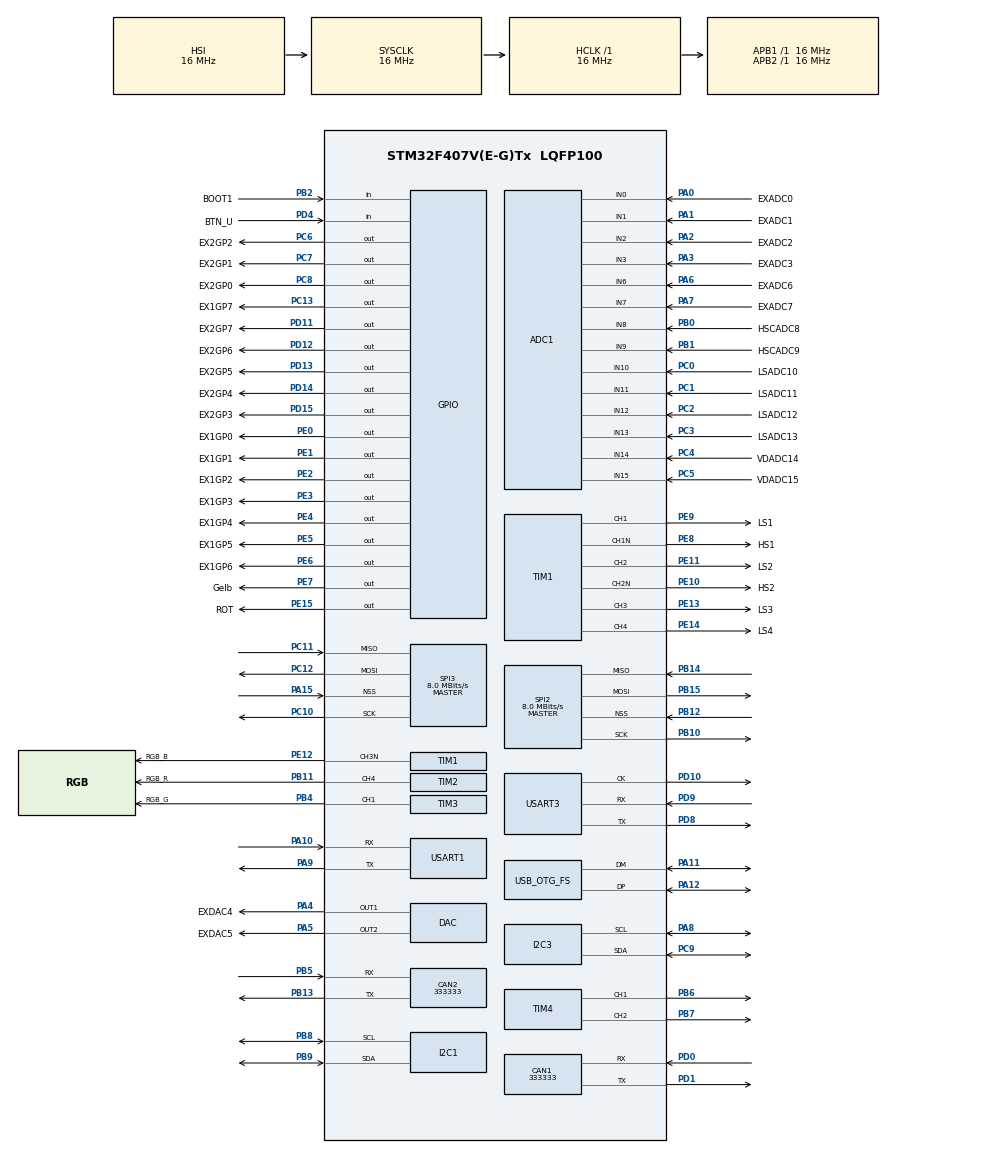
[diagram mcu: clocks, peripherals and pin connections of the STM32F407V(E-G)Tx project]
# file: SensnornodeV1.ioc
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ADC1.Channel-0\#ChannelRegularConversion=ADC_CHANNEL_10
ADC1.NbrOfConversionFlag=1
ADC1.Rank-0\#ChannelRegularConversion=1
ADC1.SamplingTime-0\#ChannelRegularConversion=ADC_SAMPLETIME_3CYCLES
ADC1.master=1
CAN1.CalculateBaudRate=333333
CAN1.CalculateTimeBit=3000
CAN1.CalculateTimeQuantum=1000.0
CAN2.CalculateBaudRate=333333
CAN2.CalculateTimeBit=3000
CAN2.CalculateTimeQuantum=1000.0
Mcu.Family=STM32F4
Mcu.Name=STM32F407V(E-G)Tx
Mcu.Package=LQFP100
NVIC.PriorityGroup=NVIC_PRIORITYGROUP_4
PA0-WKUP.GPIO_Label=EXADC0
PA0-WKUP.Signal=ADCx_IN0
PA1.GPIO_Label=EXADC1
PA1.Signal=ADCx_IN1
PA10.Mode=Asynchronous
PA10.Signal=USART1_RX
PA11.Mode=Device_Only
PA11.Signal=USB_OTG_FS_DM
PA12.Mode=Device_Only
PA12.Signal=USB_OTG_FS_DP
PA13.Mode=Trace_Asynchronous_SW
PA13.Signal=SYS_JTMS-SWDIO
PA14.Mode=Trace_Asynchronous_SW
PA14.Signal=SYS_JTCK-SWCLK
PA15.Mode=NSS_Signal_Hard_Input
PA15.Signal=SPI3_NSS
PA2.GPIO_Label=EXADC2
PA2.Signal=ADCx_IN2
PA3.GPIO_Label=EXADC3
PA3.Signal=ADCx_IN3
PA4.GPIO_Label=EXDAC4
PA4.Signal=COMP_DAC1_group
PA5.GPIO_Label=EXDAC5
PA5.Signal=COMP_DAC2_group
PA6.GPIO_Label=EXADC6
PA6.Signal=ADCx_IN6
PA7.GPIO_Label=EXADC7
PA7.Signal=ADCx_IN7
PA8.Mode=I2C
PA8.Signal=I2C3_SCL
PA9.Mode=Asynchronous
PA9.Signal=USART1_TX
PB0.GPIO_Label=HSCADC8
PB0.Signal=ADCx_IN8
PB1.GPIO_Label=HSCADC9
PB1.Signal=ADCx_IN9
PB10.Mode=Full_Duplex_Master
PB10.Signal=SPI2_SCK
PB11.GPIO_Label=RGB_R
PB11.Signal=S_TIM2_CH4
PB12.Mode=NSS_Signal_Hard_Input
PB12.Signal=SPI2_NSS
PB13.Mode=CAN_Activate
PB13.Signal=CAN2_TX
PB14.Mode=Full_Duplex_Master
PB14.Signal=SPI2_MISO
PB15.Mode=Full_Duplex_Master
PB15.Signal=SPI2_MOSI
PB2.GPIO_Label=BOOT1
PB2.Signal=GPIO_Input
PB3.Mode=Trace_Asynchronous_SW
PB3.Signal=SYS_JTDO-SWO
PB4.GPIO_Label=RGB_G
PB4.Signal=S_TIM3_CH1
PB5.Mode=CAN_Activate
PB5.Signal=CAN2_RX
PB6.Signal=S_TIM4_CH1
PB7.Signal=S_TIM4_CH2
PB8.Mode=I2C
PB8.Signal=I2C1_SCL
PB9.Mode=I2C
PB9.Signal=I2C1_SDA
PC0.GPIO_Label=LSADC10
PC0.Signal=ADCx_IN10
PC1.GPIO_Label=LSADC11
PC1.Signal=ADCx_IN11
PC10.Mode=Full_Duplex_Master
PC10.Signal=SPI3_SCK
PC11.Mode=Full_Duplex_Master
PC11.Signal=SPI3_MISO
PC12.Mode=Full_Duplex_Master
PC12.Signal=SPI3_MOSI
PC13-ANTI_TAMP.GPIO_Label=EX1GP7
PC13-ANTI_TAMP.Signal=GPIO_Output
PC2.GPIO_Label=LSADC12
PC2.Signal=ADCx_IN12
PC3.GPIO_Label=LSADC13
PC3.Signal=ADCx_IN13
PC4.GPIO_Label=VDADC14
PC4.Signal=ADCx_IN14
PC5.GPIO_Label=VDADC15
PC5.Signal=ADCx_IN15
PC6.GPIO_Label=EX2GP2
PC6.Signal=GPIO_Output
PC7.GPIO_Label=EX2GP1
PC7.Signal=GPIO_Output
PC8.GPIO_Label=EX2GP0
PC8.Signal=GPIO_Output
PC9.Mode=I2C
PC9.Signal=I2C3_SDA
PD0.Mode=CAN_Activate
PD0.Signal=CAN1_RX
PD1.Mode=CAN_Activate
PD1.Signal=CAN1_TX
PD10.Mode=Synchronous
PD10.Signal=USART3_CK
PD11.GPIO_Label=EX2GP7
PD11.Signal=GPIO_Output
PD12.GPIO_Label=EX2GP6
PD12.Signal=GPIO_Output
PD13.GPIO_Label=EX2GP5
PD13.Signal=GPIO_Output
PD14.GPIO_Label=EX2GP4
PD14.Signal=GPIO_Output
PD15.GPIO_Label=EX2GP3
PD15.Signal=GPIO_Output
PD4.GPIO_Label=BTN_U
PD4.Signal=GPIO_Input
PD8.Mode=Synchronous
PD8.Signal=USART3_TX
PD9.Mode=Synchronous
PD9.Signal=USART3_RX
PE0.GPIO_Label=EX1GP0
PE0.Signal=GPIO_Output
PE1.GPIO_Label=EX1GP1
PE1.Signal=GPIO_Output
PE10.GPIO_Label=HS2
PE10.Mode=PWM Generation2 CH2 CH2N
PE10.Signal=TIM1_CH2N
PE11.GPIO_Label=LS2
PE11.Signal=S_TIM1_CH2
PE12.GPIO_Label=RGB_B
PE12.Mode=PWM Generation3 CH3 CH3N
PE12.Signal=TIM1_CH3N
PE13.GPIO_Label=LS3
PE13.Signal=S_TIM1_CH3
PE14.GPIO_Label=LS4
PE14.Signal=S_TIM1_CH4
PE15.GPIO_Label=ROT
PE15.Signal=GPIO_Output
PE2.GPIO_Label=EX1GP2
PE2.Signal=GPIO_Output
PE3.GPIO_Label=EX1GP3
PE3.Signal=GPIO_Output
PE4.GPIO_Label=EX1GP4
PE4.Signal=GPIO_Output
PE5.GPIO_Label=EX1GP5
PE5.Signal=GPIO_Output
PE6.GPIO_Label=EX1GP6
PE6.Signal=GPIO_Output
PE7.GPIO_Label=Gelb
PE7.Signal=GPIO_Output
PE8.GPIO_Label=HS1
PE8.Mode=PWM Generation1 CH1 CH1N
PE8.Signal=TIM1_CH1N
PE9.GPIO_Label=LS1
PE9.Signal=S_TIM1_CH1
PH0-OSC_IN.Mode=HSE-External-Oscillator
PH0-OSC_IN.Signal=RCC_OSC_IN
PH1-OSC_OUT.Mode=HSE-External-Oscillator
PH1-OSC_OUT.Signal=RCC_OSC_OUT
ProjectManager.HeapSize=0x200
ProjectManager.StackSize=0x400
ProjectManager.TargetToolchain=CMake
RCC.48MHZClocksFreq_Value=48000000
RCC.AHBFreq_Value=16000000
RCC.APB1Freq_Value=16000000
RCC.APB2Freq_Value=16000000
RCC.CortexFreq_Value=16000000
RCC.HSE_VALUE=25000000
RCC.HSI_VALUE=16000000
RCC.LSE_VALUE=32768
RCC.PLLM=15
RCC.PLLN=144
RCC.PLLQ=5
RCC.SYSCLKFreq_VALUE=16000000
RCC.VCOOutputFreq_Value=240000000
SH.ADCx_IN0.0=ADC1_IN0,IN0
SH.ADCx_IN1.0=ADC1_IN1,IN1
SH.ADCx_IN10.0=ADC1_IN10,IN10
SH.ADCx_IN11.0=ADC1_IN11,IN11
SH.ADCx_IN12.0=ADC1_IN12,IN12
SH.ADCx_IN13.0=ADC1_IN13,IN13
SH.ADCx_IN14.0=ADC1_IN14,IN14
SH.ADCx_IN15.0=ADC1_IN15,IN15
SH.ADCx_IN2.0=ADC1_IN2,IN2
SH.ADCx_IN3.0=ADC1_IN3,IN3
SH.ADCx_IN6.0=ADC1_IN6,IN6
SH.ADCx_IN7.0=ADC1_IN7,IN7
SH.ADCx_IN8.0=ADC1_IN8,IN8
SH.ADCx_IN9.0=ADC1_IN9,IN9
SH.COMP_DAC1_group.0=DAC_OUT1,DAC_OUT1
SH.COMP_DAC2_group.0=DAC_OUT2,DAC_OUT2
SH.S_TIM1_CH1.0=TIM1_CH1,PWM Generation1 CH1 CH1N
SH.S_TIM1_CH2.0=TIM1_CH2,PWM Generation2 CH2 CH2N
SH.S_TIM1_CH3.0=TIM1_CH3,PWM Generation3 CH3 CH3N
SH.S_TIM1_CH4.0=TIM1_CH4,PWM Generation4 CH4
SH.S_TIM2_CH4.0=TIM2_CH4,Forced Output4 CH4
SH.S_TIM3_CH1.0=TIM3_CH1,PWM Generation1 CH1
SH.S_TIM4_CH1.0=TIM4_CH1,PWM Generation1 CH1
SH.S_TIM4_CH2.0=TIM4_CH2,PWM Generation2 CH2
SPI2.CalculateBaudRate=8.0 MBits/s
SPI2.Direction=SPI_DIRECTION_2LINES
SPI2.Mode=SPI_MODE_MASTER
SPI2.VirtualNSS=VM_NSSHARD
SPI2.VirtualType=VM_MASTER
SPI3.CalculateBaudRate=8.0 MBits/s
SPI3.Direction=SPI_DIRECTION_2LINES
SPI3.Mode=SPI_MODE_MASTER
SPI3.VirtualNSS=VM_NSSHARD
SPI3.VirtualType=VM_MASTER
TIM1.Channel-PWM\ Generation1\ CH1\ CH1N=TIM_CHANNEL_1
TIM1.Channel-PWM\ Generation2\ CH2\ CH2N=TIM_CHANNEL_2
TIM1.Channel-PWM\ Generation3\ CH3\ CH3N=TIM_CHANNEL_3
TIM1.Channel-PWM\ Generation4\ CH4=TIM_CHANNEL_4
TIM2.Channel-Forced\ Output4\ CH4=TIM_CHANNEL_4
TIM3.Channel-PWM\ Generation1\ CH1=TIM_CHANNEL_1
TIM4.Channel-PWM\ Generation1\ CH1=TIM_CHANNEL_1
TIM4.Channel-PWM\ Generation2\ CH2=TIM_CHANNEL_2
USART1.VirtualMode=VM_ASYNC
USART3.VirtualMode=VM_SYNC
USB_OTG_FS.VirtualMode=Device_Only
board=custom

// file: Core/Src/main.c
/* USER CODE BEGIN Header */
/**
  ******************************************************************************
  * @file           : main.c
  * @brief          : Main program body
  ******************************************************************************
  * @attention
  *
  * Copyright (c) 2026 STMicroelectronics.
  * All rights reserved.
  *
  * This software is licensed under terms that can be found in the LICENSE file
  * in the root directory of this software component.
  * If no LICENSE file comes with this software, it is provided AS-IS.
  *
  ******************************************************************************
  */
/* USER CODE END Header */
#include "main.h"

/* USER CODE BEGIN Includes */
#include "Tester/TestMain.h"
/* USER CODE END Includes */

ADC_HandleTypeDef hadc1;

CAN_HandleTypeDef hcan1;
CAN_HandleTypeDef hcan2;

DAC_HandleTypeDef hdac;

I2C_HandleTypeDef hi2c1;
I2C_HandleTypeDef hi2c3;

SPI_HandleTypeDef hspi2;
SPI_HandleTypeDef hspi3;

TIM_HandleTypeDef htim1;
TIM_HandleTypeDef htim2;
TIM_HandleTypeDef htim3;
TIM_HandleTypeDef htim4;

UART_HandleTypeDef huart1;
USART_HandleTypeDef husart3;

PCD_HandleTypeDef hpcd_USB_OTG_FS;

void SystemClock_Config(void);
static void MX_GPIO_Init(void);
static void MX_ADC1_Init(void);
static void MX_CAN1_Init(void);
static void MX_CAN2_Init(void);
static void MX_DAC_Init(void);
static void MX_I2C1_Init(void);
static void MX_I2C3_Init(void);
static void MX_SPI2_Init(void);
static void MX_SPI3_Init(void);
static void MX_TIM1_Init(void);
static void MX_TIM2_Init(void);
static void MX_TIM3_Init(void);
static void MX_TIM4_Init(void);
static void MX_USART1_UART_Init(void);
static void MX_USART3_Init(void);
static void MX_USB_OTG_FS_PCD_Init(void);

int main(void)
{

  /* MCU Configuration--------------------------------------------------------*/

  /* Reset of all peripherals, Initializes the Flash interface and the Systick. */
  HAL_Init();

  /* Configure the system clock */
  SystemClock_Config();

  /* Initialize all configured peripherals */
  MX_GPIO_Init();
  MX_ADC1_Init();
  MX_CAN1_Init();
  MX_CAN2_Init();
  MX_DAC_Init();
  MX_I2C1_Init();
  MX_I2C3_Init();
  MX_SPI2_Init();
  MX_SPI3_Init();
  MX_TIM1_Init();
  MX_TIM2_Init();
  MX_TIM3_Init();
  MX_TIM4_Init();
  MX_USART1_UART_Init();
  MX_USART3_Init();
  MX_USB_OTG_FS_PCD_Init();

  /* Infinite loop */
  while (1)
  {

  while (1)
  {
  }
}

void SystemClock_Config(void)
{
  RCC_OscInitTypeDef RCC_OscInitStruct = {0};
  RCC_ClkInitTypeDef RCC_ClkInitStruct = {0};

  /** Configure the main internal regulator output voltage
  */
  __HAL_RCC_PWR_CLK_ENABLE();
  __HAL_PWR_VOLTAGESCALING_CONFIG(PWR_REGULATOR_VOLTAGE_SCALE1);

  /** Initializes the RCC Oscillators according to the specified parameters
  * in the RCC_OscInitTypeDef structure.
  */
  RCC_OscInitStruct.OscillatorType = RCC_OSCILLATORTYPE_HSI|RCC_OSCILLATORTYPE_HSE;
  RCC_OscInitStruct.HSEState = RCC_HSE_ON;
  RCC_OscInitStruct.HSIState = RCC_HSI_ON;
  RCC_OscInitStruct.HSICalibrationValue = RCC_HSICALIBRATION_DEFAULT;
  RCC_OscInitStruct.PLL.PLLState = RCC_PLL_ON;
  RCC_OscInitStruct.PLL.PLLSource = RCC_PLLSOURCE_HSE;
  RCC_OscInitStruct.PLL.PLLM = 15;
  RCC_OscInitStruct.PLL.PLLN = 144;
  RCC_OscInitStruct.PLL.PLLP = RCC_PLLP_DIV2;
  RCC_OscInitStruct.PLL.PLLQ = 5;
  if (HAL_RCC_OscConfig(&RCC_OscInitStruct) != HAL_OK)
  {
    Error_Handler();
  }

  /** Initializes the CPU, AHB and APB buses clocks
  */
  RCC_ClkInitStruct.ClockType = RCC_CLOCKTYPE_HCLK|RCC_CLOCKTYPE_SYSCLK
                              |RCC_CLOCKTYPE_PCLK1|RCC_CLOCKTYPE_PCLK2;
  RCC_ClkInitStruct.SYSCLKSource = RCC_SYSCLKSOURCE_HSI;
  RCC_ClkInitStruct.AHBCLKDivider = RCC_SYSCLK_DIV1;
  RCC_ClkInitStruct.APB1CLKDivider = RCC_HCLK_DIV1;
  RCC_ClkInitStruct.APB2CLKDivider = RCC_HCLK_DIV1;

  if (HAL_RCC_ClockConfig(&RCC_ClkInitStruct, FLASH_LATENCY_0) != HAL_OK)
  {
    Error_Handler();
  }
}

static void MX_ADC1_Init(void)
{

  ADC_ChannelConfTypeDef sConfig = {0};

  /** Configure the global features of the ADC (Clock, Resolution, Data Alignment and number of conversion)
  */
  hadc1.Instance = ADC1;
  hadc1.Init.ClockPrescaler = ADC_CLOCK_SYNC_PCLK_DIV2;
  hadc1.Init.Resolution = ADC_RESOLUTION_12B;
  hadc1.Init.ScanConvMode = DISABLE;
  hadc1.Init.ContinuousConvMode = DISABLE;
  hadc1.Init.DiscontinuousConvMode = DISABLE;
  hadc1.Init.ExternalTrigConvEdge = ADC_EXTERNALTRIGCONVEDGE_NONE;
  hadc1.Init.ExternalTrigConv = ADC_SOFTWARE_START;
  hadc1.Init.DataAlign = ADC_DATAALIGN_RIGHT;
  hadc1.Init.NbrOfConversion = 1;
  hadc1.Init.DMAContinuousRequests = DISABLE;
  hadc1.Init.EOCSelection = ADC_EOC_SINGLE_CONV;
  if (HAL_ADC_Init(&hadc1) != HAL_OK)
  {
    Error_Handler();
  }

  /** Configure for the selected ADC regular channel its corresponding rank in the sequencer and its sample time.
  */
  sConfig.Channel = ADC_CHANNEL_10;
  sConfig.Rank = 1;
  sConfig.SamplingTime = ADC_SAMPLETIME_3CYCLES;
  if (HAL_ADC_ConfigChannel(&hadc1, &sConfig) != HAL_OK)
  {
    Error_Handler();
  }

}

static void MX_CAN1_Init(void)
{

  hcan1.Instance = CAN1;
  hcan1.Init.Prescaler = 16;
  hcan1.Init.Mode = CAN_MODE_NORMAL;
  hcan1.Init.SyncJumpWidth = CAN_SJW_1TQ;
  hcan1.Init.TimeSeg1 = CAN_BS1_1TQ;
  hcan1.Init.TimeSeg2 = CAN_BS2_1TQ;
  hcan1.Init.TimeTriggeredMode = DISABLE;
  hcan1.Init.AutoBusOff = DISABLE;
  hcan1.Init.AutoWakeUp = DISABLE;
  hcan1.Init.AutoRetransmission = DISABLE;
  hcan1.Init.ReceiveFifoLocked = DISABLE;
  hcan1.Init.TransmitFifoPriority = DISABLE;
  if (HAL_CAN_Init(&hcan1) != HAL_OK)
  {
    Error_Handler();
  }

}

static void MX_CAN2_Init(void)
{

  hcan2.Instance = CAN2;
  hcan2.Init.Prescaler = 16;
  hcan2.Init.Mode = CAN_MODE_NORMAL;
  hcan2.Init.SyncJumpWidth = CAN_SJW_1TQ;
  hcan2.Init.TimeSeg1 = CAN_BS1_1TQ;
  hcan2.Init.TimeSeg2 = CAN_BS2_1TQ;
  hcan2.Init.TimeTriggeredMode = DISABLE;
  hcan2.Init.AutoBusOff = DISABLE;
  hcan2.Init.AutoWakeUp = DISABLE;
  hcan2.Init.AutoRetransmission = DISABLE;
  hcan2.Init.ReceiveFifoLocked = DISABLE;
  hcan2.Init.TransmitFifoPriority = DISABLE;
  if (HAL_CAN_Init(&hcan2) != HAL_OK)
  {
    Error_Handler();
  }

}

static void MX_DAC_Init(void)
{

  DAC_ChannelConfTypeDef sConfig = {0};

  /** DAC Initialization
  */
  hdac.Instance = DAC;
  if (HAL_DAC_Init(&hdac) != HAL_OK)
  {
    Error_Handler();
  }

  /** DAC channel OUT1 config
  */
  sConfig.DAC_Trigger = DAC_TRIGGER_NONE;
  sConfig.DAC_OutputBuffer = DAC_OUTPUTBUFFER_ENABLE;
  if (HAL_DAC_ConfigChannel(&hdac, &sConfig, DAC_CHANNEL_1) != HAL_OK)
  {
    Error_Handler();
  }

  /** DAC channel OUT2 config
  */
  if (HAL_DAC_ConfigChannel(&hdac, &sConfig, DAC_CHANNEL_2) != HAL_OK)
  {
    Error_Handler();
  }

}

static void MX_I2C1_Init(void)
{

  hi2c1.Instance = I2C1;
  hi2c1.Init.ClockSpeed = 100000;
  hi2c1.Init.DutyCycle = I2C_DUTYCYCLE_2;
  hi2c1.Init.OwnAddress1 = 0;
  hi2c1.Init.AddressingMode = I2C_ADDRESSINGMODE_7BIT;
  hi2c1.Init.DualAddressMode = I2C_DUALADDRESS_DISABLE;
  hi2c1.Init.OwnAddress2 = 0;
  hi2c1.Init.GeneralCallMode = I2C_GENERALCALL_DISABLE;
  hi2c1.Init.NoStretchMode = I2C_NOSTRETCH_DISABLE;
  if (HAL_I2C_Init(&hi2c1) != HAL_OK)
  {
    Error_Handler();
  }

}

static void MX_I2C3_Init(void)
{

  hi2c3.Instance = I2C3;
  hi2c3.Init.ClockSpeed = 100000;
  hi2c3.Init.DutyCycle = I2C_DUTYCYCLE_2;
  hi2c3.Init.OwnAddress1 = 0;
  hi2c3.Init.AddressingMode = I2C_ADDRESSINGMODE_7BIT;
  hi2c3.Init.DualAddressMode = I2C_DUALADDRESS_DISABLE;
  hi2c3.Init.OwnAddress2 = 0;
  hi2c3.Init.GeneralCallMode = I2C_GENERALCALL_DISABLE;
  hi2c3.Init.NoStretchMode = I2C_NOSTRETCH_DISABLE;
  if (HAL_I2C_Init(&hi2c3) != HAL_OK)
  {
    Error_Handler();
  }

}

static void MX_SPI2_Init(void)
{

  /* SPI2 parameter configuration*/
  hspi2.Instance = SPI2;
  hspi2.Init.Mode = SPI_MODE_MASTER;
  hspi2.Init.Direction = SPI_DIRECTION_2LINES;
  hspi2.Init.DataSize = SPI_DATASIZE_8BIT;
  hspi2.Init.CLKPolarity = SPI_POLARITY_LOW;
  hspi2.Init.CLKPhase = SPI_PHASE_1EDGE;
  hspi2.Init.NSS = SPI_NSS_HARD_INPUT;
  hspi2.Init.BaudRatePrescaler = SPI_BAUDRATEPRESCALER_2;
  hspi2.Init.FirstBit = SPI_FIRSTBIT_MSB;
  hspi2.Init.TIMode = SPI_TIMODE_DISABLE;
  hspi2.Init.CRCCalculation = SPI_CRCCALCULATION_DISABLE;
  hspi2.Init.CRCPolynomial = 10;
  if (HAL_SPI_Init(&hspi2) != HAL_OK)
  {
    Error_Handler();
  }

}

static void MX_SPI3_Init(void)
{

  /* SPI3 parameter configuration*/
  hspi3.Instance = SPI3;
  hspi3.Init.Mode = SPI_MODE_MASTER;
  hspi3.Init.Direction = SPI_DIRECTION_2LINES;
  hspi3.Init.DataSize = SPI_DATASIZE_8BIT;
  hspi3.Init.CLKPolarity = SPI_POLARITY_LOW;
  hspi3.Init.CLKPhase = SPI_PHASE_1EDGE;
  hspi3.Init.NSS = SPI_NSS_HARD_INPUT;
  hspi3.Init.BaudRatePrescaler = SPI_BAUDRATEPRESCALER_2;
  hspi3.Init.FirstBit = SPI_FIRSTBIT_MSB;
  hspi3.Init.TIMode = SPI_TIMODE_DISABLE;
  hspi3.Init.CRCCalculation = SPI_CRCCALCULATION_DISABLE;
  hspi3.Init.CRCPolynomial = 10;
  if (HAL_SPI_Init(&hspi3) != HAL_OK)
  {
    Error_Handler();
  }

}

static void MX_TIM1_Init(void)
{

  TIM_MasterConfigTypeDef sMasterConfig = {0};
  TIM_OC_InitTypeDef sConfigOC = {0};
  TIM_BreakDeadTimeConfigTypeDef sBreakDeadTimeConfig = {0};

  htim1.Instance = TIM1;
  htim1.Init.Prescaler = 0;
  htim1.Init.CounterMode = TIM_COUNTERMODE_UP;
  htim1.Init.Period = 65535;
  htim1.Init.ClockDivision = TIM_CLOCKDIVISION_DIV1;
  htim1.Init.RepetitionCounter = 0;
  htim1.Init.AutoReloadPreload = TIM_AUTORELOAD_PRELOAD_DISABLE;
  if (HAL_TIM_PWM_Init(&htim1) != HAL_OK)
  {
    Error_Handler();
  }
  sMasterConfig.MasterOutputTrigger = TIM_TRGO_RESET;
  sMasterConfig.MasterSlaveMode = TIM_MASTERSLAVEMODE_DISABLE;
  if (HAL_TIMEx_MasterConfigSynchronization(&htim1, &sMasterConfig) != HAL_OK)
  {
    Error_Handler();
  }
  sConfigOC.OCMode = TIM_OCMODE_PWM1;
  sConfigOC.Pulse = 0;
  sConfigOC.OCPolarity = TIM_OCPOLARITY_HIGH;
  sConfigOC.OCNPolarity = TIM_OCNPOLARITY_HIGH;
  sConfigOC.OCFastMode = TIM_OCFAST_DISABLE;
  sConfigOC.OCIdleState = TIM_OCIDLESTATE_RESET;
  sConfigOC.OCNIdleState = TIM_OCNIDLESTATE_RESET;
  if (HAL_TIM_PWM_ConfigChannel(&htim1, &sConfigOC, TIM_CHANNEL_1) != HAL_OK)
  {
    Error_Handler();
  }
  if (HAL_TIM_PWM_ConfigChannel(&htim1, &sConfigOC, TIM_CHANNEL_2) != HAL_OK)
  {
    Error_Handler();
  }
  if (HAL_TIM_PWM_ConfigChannel(&htim1, &sConfigOC, TIM_CHANNEL_3) != HAL_OK)
  {
    Error_Handler();
  }
  if (HAL_TIM_PWM_ConfigChannel(&htim1, &sConfigOC, TIM_CHANNEL_4) != HAL_OK)
  {
    Error_Handler();
  }
  sBreakDeadTimeConfig.OffStateRunMode = TIM_OSSR_DISABLE;
  sBreakDeadTimeConfig.OffStateIDLEMode = TIM_OSSI_DISABLE;
  sBreakDeadTimeConfig.LockLevel = TIM_LOCKLEVEL_OFF;
  sBreakDeadTimeConfig.DeadTime = 0;
  sBreakDeadTimeConfig.BreakState = TIM_BREAK_DISABLE;
  sBreakDeadTimeConfig.BreakPolarity = TIM_BREAKPOLARITY_HIGH;
  sBreakDeadTimeConfig.AutomaticOutput = TIM_AUTOMATICOUTPUT_DISABLE;
  if (HAL_TIMEx_ConfigBreakDeadTime(&htim1, &sBreakDeadTimeConfig) != HAL_OK)
  {
    Error_Handler();
  }
  HAL_TIM_MspPostInit(&htim1);

}

static void MX_TIM2_Init(void)
{

  TIM_MasterConfigTypeDef sMasterConfig = {0};
  TIM_OC_InitTypeDef sConfigOC = {0};

  htim2.Instance = TIM2;
  htim2.Init.Prescaler = 0;
  htim2.Init.CounterMode = TIM_COUNTERMODE_UP;
  htim2.Init.Period = 4294967295;
  htim2.Init.ClockDivision = TIM_CLOCKDIVISION_DIV1;
  htim2.Init.AutoReloadPreload = TIM_AUTORELOAD_PRELOAD_DISABLE;
  if (HAL_TIM_OC_Init(&htim2) != HAL_OK)
  {
    Error_Handler();
  }
  sMasterConfig.MasterOutputTrigger = TIM_TRGO_RESET;
  sMasterConfig.MasterSlaveMode = TIM_MASTERSLAVEMODE_DISABLE;
  if (HAL_TIMEx_MasterConfigSynchronization(&htim2, &sMasterConfig) != HAL_OK)
  {
    Error_Handler();
  }
  sConfigOC.OCMode = TIM_OCMODE_FORCED_ACTIVE;
  sConfigOC.Pulse = 0;
  sConfigOC.OCPolarity = TIM_OCPOLARITY_HIGH;
  sConfigOC.OCFastMode = TIM_OCFAST_DISABLE;
  if (HAL_TIM_OC_ConfigChannel(&htim2, &sConfigOC, TIM_CHANNEL_4) != HAL_OK)
  {
    Error_Handler();
  }
  HAL_TIM_MspPostInit(&htim2);

}

static void MX_TIM3_Init(void)
{

  TIM_MasterConfigTypeDef sMasterConfig = {0};
  TIM_OC_InitTypeDef sConfigOC = {0};

  htim3.Instance = TIM3;
  htim3.Init.Prescaler = 0;
  htim3.Init.CounterMode = TIM_COUNTERMODE_UP;
  htim3.Init.Period = 65535;
  htim3.Init.ClockDivision = TIM_CLOCKDIVISION_DIV1;
  htim3.Init.AutoReloadPreload = TIM_AUTORELOAD_PRELOAD_DISABLE;
  if (HAL_TIM_PWM_Init(&htim3) != HAL_OK)
  {
    Error_Handler();
  }
  sMasterConfig.MasterOutputTrigger = TIM_TRGO_RESET;
  sMasterConfig.MasterSlaveMode = TIM_MASTERSLAVEMODE_DISABLE;
  if (HAL_TIMEx_MasterConfigSynchronization(&htim3, &sMasterConfig) != HAL_OK)
  {
    Error_Handler();
  }
  sConfigOC.OCMode = TIM_OCMODE_PWM1;
  sConfigOC.Pulse = 0;
  sConfigOC.OCPolarity = TIM_OCPOLARITY_HIGH;
  sConfigOC.OCFastMode = TIM_OCFAST_DISABLE;
  if (HAL_TIM_PWM_ConfigChannel(&htim3, &sConfigOC, TIM_CHANNEL_1) != HAL_OK)
  {
    Error_Handler();
  }
  HAL_TIM_MspPostInit(&htim3);

}

static void MX_TIM4_Init(void)
{

  TIM_MasterConfigTypeDef sMasterConfig = {0};
  TIM_OC_InitTypeDef sConfigOC = {0};

  htim4.Instance = TIM4;
  htim4.Init.Prescaler = 0;
  htim4.Init.CounterMode = TIM_COUNTERMODE_UP;
  htim4.Init.Period = 65535;
  htim4.Init.ClockDivision = TIM_CLOCKDIVISION_DIV1;
  htim4.Init.AutoReloadPreload = TIM_AUTORELOAD_PRELOAD_DISABLE;
  if (HAL_TIM_PWM_Init(&htim4) != HAL_OK)
  {
    Error_Handler();
  }
  sMasterConfig.MasterOutputTrigger = TIM_TRGO_RESET;
  sMasterConfig.MasterSlaveMode = TIM_MASTERSLAVEMODE_DISABLE;
  if (HAL_TIMEx_MasterConfigSynchronization(&htim4, &sMasterConfig) != HAL_OK)
  {
    Error_Handler();
  }
  sConfigOC.OCMode = TIM_OCMODE_PWM1;
  sConfigOC.Pulse = 0;
  sConfigOC.OCPolarity = TIM_OCPOLARITY_HIGH;
  sConfigOC.OCFastMode = TIM_OCFAST_DISABLE;
  if (HAL_TIM_PWM_ConfigChannel(&htim4, &sConfigOC, TIM_CHANNEL_1) != HAL_OK)
  {
    Error_Handler();
  }
  if (HAL_TIM_PWM_ConfigChannel(&htim4, &sConfigOC, TIM_CHANNEL_2) != HAL_OK)
  {
    Error_Handler();
  }
  HAL_TIM_MspPostInit(&htim4);

}

static void MX_USART1_UART_Init(void)
{

  huart1.Instance = USART1;
  huart1.Init.BaudRate = 115200;
  huart1.Init.WordLength = UART_WORDLENGTH_8B;
  huart1.Init.StopBits = UART_STOPBITS_1;
  huart1.Init.Parity = UART_PARITY_NONE;
  huart1.Init.Mode = UART_MODE_TX_RX;
  huart1.Init.HwFlowCtl = UART_HWCONTROL_NONE;
  huart1.Init.OverSampling = UART_OVERSAMPLING_16;
  if (HAL_UART_Init(&huart1) != HAL_OK)
  {
    Error_Handler();
  }

}

static void MX_USART3_Init(void)
{

  husart3.Instance = USART3;
  husart3.Init.BaudRate = 115200;
  husart3.Init.WordLength = USART_WORDLENGTH_8B;
  husart3.Init.StopBits = USART_STOPBITS_1;
  husart3.Init.Parity = USART_PARITY_NONE;
  husart3.Init.Mode = USART_MODE_TX_RX;
  husart3.Init.CLKPolarity = USART_POLARITY_LOW;
  husart3.Init.CLKPhase = USART_PHASE_1EDGE;
  husart3.Init.CLKLastBit = USART_LASTBIT_DISABLE;
  if (HAL_USART_Init(&husart3) != HAL_OK)
  {
    Error_Handler();
  }

}

static void MX_USB_OTG_FS_PCD_Init(void)
{

  hpcd_USB_OTG_FS.Instance = USB_OTG_FS;
  hpcd_USB_OTG_FS.Init.dev_endpoints = 4;
  hpcd_USB_OTG_FS.Init.speed = PCD_SPEED_FULL;
  hpcd_USB_OTG_FS.Init.dma_enable = DISABLE;
  hpcd_USB_OTG_FS.Init.phy_itface = PCD_PHY_EMBEDDED;
  hpcd_USB_OTG_FS.Init.Sof_enable = DISABLE;
  hpcd_USB_OTG_FS.Init.low_power_enable = DISABLE;
  hpcd_USB_OTG_FS.Init.lpm_enable = DISABLE;
  hpcd_USB_OTG_FS.Init.vbus_sensing_enable = DISABLE;
  hpcd_USB_OTG_FS.Init.use_dedicated_ep1 = DISABLE;
  if (HAL_PCD_Init(&hpcd_USB_OTG_FS) != HAL_OK)
  {
    Error_Handler();
  }

}

static void MX_GPIO_Init(void)
{
  GPIO_InitTypeDef GPIO_InitStruct = {0};

  /* GPIO Ports Clock Enable */
  __HAL_RCC_GPIOE_CLK_ENABLE();
  __HAL_RCC_GPIOC_CLK_ENABLE();
  __HAL_RCC_GPIOH_CLK_ENABLE();
  __HAL_RCC_GPIOA_CLK_ENABLE();
  __HAL_RCC_GPIOB_CLK_ENABLE();
  __HAL_RCC_GPIOD_CLK_ENABLE();

  /*Configure GPIO pin Output Level */
  HAL_GPIO_WritePin(GPIOE, EX1GP2_Pin|EX1GP3_Pin|EX1GP4_Pin|EX1GP5_Pin
                          |EX1GP6_Pin|Gelb_Pin|ROT_Pin|EX1GP0_Pin
                          |EX1GP1_Pin, GPIO_PIN_RESET);

  /*Configure GPIO pin Output Level */
  HAL_GPIO_WritePin(GPIOC, EX1GP7_Pin|EX2GP2_Pin|EX2GP1_Pin|EX2GP0_Pin, GPIO_PIN_RESET);

  /*Configure GPIO pin Output Level */
  HAL_GPIO_WritePin(GPIOD, EX2GP7_Pin|EX2GP6_Pin|EX2GP5_Pin|EX2GP4_Pin
                          |EX2GP3_Pin, GPIO_PIN_RESET);

  /*Configure GPIO pins : EX1GP2_Pin EX1GP3_Pin EX1GP4_Pin EX1GP5_Pin
                           EX1GP6_Pin Gelb_Pin ROT_Pin EX1GP0_Pin
                           EX1GP1_Pin */
  GPIO_InitStruct.Pin = EX1GP2_Pin|EX1GP3_Pin|EX1GP4_Pin|EX1GP5_Pin
                          |EX1GP6_Pin|Gelb_Pin|ROT_Pin|EX1GP0_Pin
                          |EX1GP1_Pin;
  GPIO_InitStruct.Mode = GPIO_MODE_OUTPUT_PP;
  GPIO_InitStruct.Pull = GPIO_NOPULL;
  GPIO_InitStruct.Speed = GPIO_SPEED_FREQ_LOW;
  HAL_GPIO_Init(GPIOE, &GPIO_InitStruct);

  /*Configure GPIO pins : EX1GP7_Pin EX2GP2_Pin EX2GP1_Pin EX2GP0_Pin */
  GPIO_InitStruct.Pin = EX1GP7_Pin|EX2GP2_Pin|EX2GP1_Pin|EX2GP0_Pin;
  GPIO_InitStruct.Mode = GPIO_MODE_OUTPUT_PP;
  GPIO_InitStruct.Pull = GPIO_NOPULL;
  GPIO_InitStruct.Speed = GPIO_SPEED_FREQ_LOW;
  HAL_GPIO_Init(GPIOC, &GPIO_InitStruct);

  /*Configure GPIO pin : BOOT1_Pin */
  GPIO_InitStruct.Pin = BOOT1_Pin;
  GPIO_InitStruct.Mode = GPIO_MODE_INPUT;
  GPIO_InitStruct.Pull = GPIO_NOPULL;
  HAL_GPIO_Init(BOOT1_GPIO_Port, &GPIO_InitStruct);

  /*Configure GPIO pins : EX2GP7_Pin EX2GP6_Pin EX2GP5_Pin EX2GP4_Pin
                           EX2GP3_Pin */
  GPIO_InitStruct.Pin = EX2GP7_Pin|EX2GP6_Pin|EX2GP5_Pin|EX2GP4_Pin
                          |EX2GP3_Pin;
  GPIO_InitStruct.Mode = GPIO_MODE_OUTPUT_PP;
  GPIO_InitStruct.Pull = GPIO_NOPULL;
  GPIO_InitStruct.Speed = GPIO_SPEED_FREQ_LOW;
  HAL_GPIO_Init(GPIOD, &GPIO_InitStruct);

  /*Configure GPIO pin : BTN_U_Pin */
  GPIO_InitStruct.Pin = BTN_U_Pin;
  GPIO_InitStruct.Mode = GPIO_MODE_INPUT;
  GPIO_InitStruct.Pull = GPIO_NOPULL;
  HAL_GPIO_Init(BTN_U_GPIO_Port, &GPIO_InitStruct);

}

void Error_Handler(void)
{
  __disable_irq();
  while (1)
  {
  }
}
